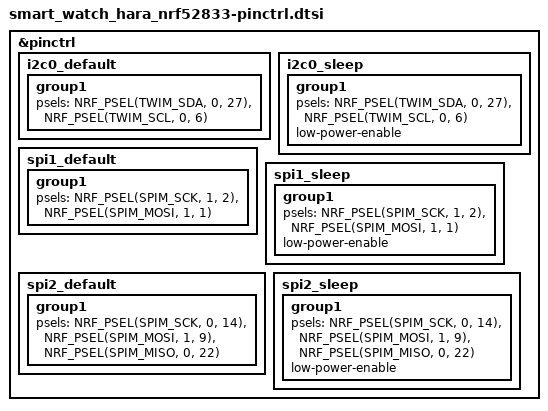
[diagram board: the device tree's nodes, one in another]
/*
 * Copyright (c) 2022 Nordic Semiconductor
 * SPDX-License-Identifier: Apache-2.0
 */

&pinctrl {
	// TODO remove for actual watch, no UART

	i2c0_default: i2c0_default {
		group1 {
			psels = <NRF_PSEL(TWIM_SDA, 0, 27)>,
					<NRF_PSEL(TWIM_SCL, 0, 6)>;
		};
	};

	i2c0_sleep: i2c0_sleep {
		group1 {
			psels = <NRF_PSEL(TWIM_SDA, 0, 27)>,
					<NRF_PSEL(TWIM_SCL, 0, 6)>;
			low-power-enable;
		};
	};

	spi1_default: spi1_default {
		group1 {
			// psels = <NRF_PSEL(SPIM_SCK, 0, 1)>,
					   // <NRF_PSEL(SPIM_MOSI, 0, 0)>;
			//<NRF_PSEL(SPIM_MISO, 0, 0)>;
			psels = <NRF_PSEL(SPIM_SCK, 1, 2)>,
					<NRF_PSEL(SPIM_MOSI, 1, 1)>;

		};
	};

	spi1_sleep: spi1_sleep {
		group1 {
			psels = <NRF_PSEL(SPIM_SCK, 1, 2)>,
					<NRF_PSEL(SPIM_MOSI, 1, 1)>;
			//<NRF_PSEL(SPIM_MISO, 0, 0)>;
			low-power-enable;
		};
	};

	spi2_default: spi2_default {
		group1 {
			psels = <NRF_PSEL(SPIM_SCK, 0, 14)>,
			        <NRF_PSEL(SPIM_MOSI, 1, 9)>,
			        <NRF_PSEL(SPIM_MISO, 0, 22)>;
		};
	};

	spi2_sleep: spi2_sleep {
		group1 {
			psels = <NRF_PSEL(SPIM_SCK, 0, 14)>,
			        <NRF_PSEL(SPIM_MOSI, 1, 9)>,
			        <NRF_PSEL(SPIM_MISO, 0, 22)>;
			low-power-enable;
		};
	};
};
